VERSION "solectrac-re-0.1"

NS_ :

BS_:

BU_: BMS Charger Dashboard MotorECU VehicleController

BO_ 2565931216 VC_Status: 8 VehicleController
 SG_ VC_State : 7|8@0+ (1,0) [0|255] "" BMS,Charger,MotorECU

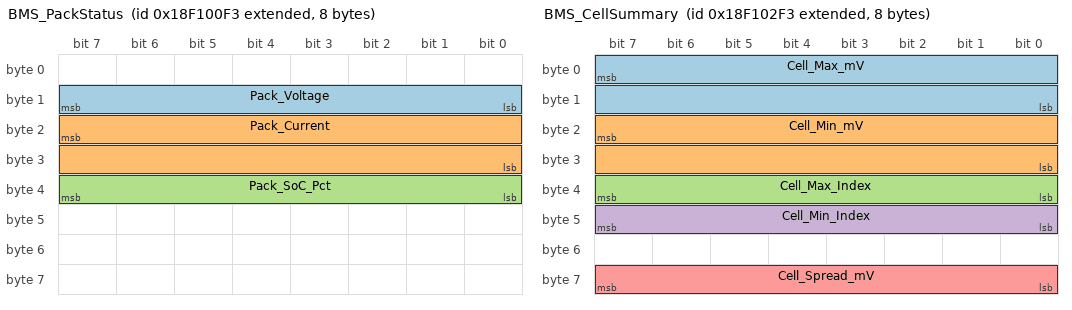
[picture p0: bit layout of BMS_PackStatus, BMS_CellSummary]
BO_ 2565931251 BMS_PackStatus: 8 BMS
 SG_ Pack_Voltage : 15|8@0+ (0.1,76.8) [76.8|102.3] "V" VehicleController,Charger,MotorECU
 SG_ Pack_Current : 23|16@0+ (0.1,-3200) [-3200|3353.5] "A" VehicleController,Charger,MotorECU
 SG_ Pack_SoC_Pct : 39|8@0+ (0.385,3.8) [0|101.975] "%" VehicleController,Charger,MotorECU

BO_ 2565931763 BMS_CellSummary: 8 BMS
 SG_ Cell_Max_mV : 7|16@0+ (1,0) [0|65535] "mV" VehicleController
 SG_ Cell_Min_mV : 23|16@0+ (1,0) [0|65535] "mV" VehicleController
 SG_ Cell_Max_Index : 39|8@0+ (1,0) [0|255] "" VehicleController
 SG_ Cell_Min_Index : 47|8@0+ (1,0) [0|255] "" VehicleController
 SG_ Cell_Spread_mV : 63|8@0+ (1,0) [0|255] "mV" VehicleController

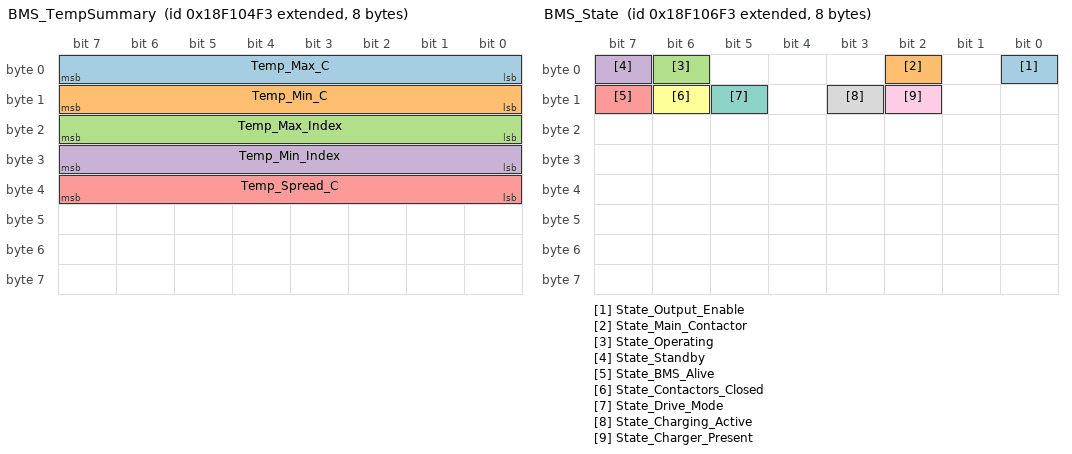
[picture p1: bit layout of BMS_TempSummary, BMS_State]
BO_ 2565932275 BMS_TempSummary: 8 BMS
 SG_ Temp_Max_C : 7|8@0+ (1,-40) [-40|215] "degC" VehicleController
 SG_ Temp_Min_C : 15|8@0+ (1,-40) [-40|215] "degC" VehicleController
 SG_ Temp_Max_Index : 23|8@0+ (1,0) [0|255] "" VehicleController
 SG_ Temp_Min_Index : 31|8@0+ (1,0) [0|255] "" VehicleController
 SG_ Temp_Spread_C : 39|8@0+ (1,0) [0|255] "degC" VehicleController

BO_ 2565932787 BMS_State: 8 BMS
 SG_ State_Output_Enable : 0|1@1+ (1,0) [0|1] "" VehicleController
 SG_ State_Main_Contactor : 2|1@1+ (1,0) [0|1] "" VehicleController
 SG_ State_Operating : 6|1@1+ (1,0) [0|1] "" VehicleController
 SG_ State_Standby : 7|1@1+ (1,0) [0|1] "" VehicleController
 SG_ State_BMS_Alive : 15|1@1+ (1,0) [0|1] "" VehicleController
 SG_ State_Contactors_Closed : 14|1@1+ (1,0) [0|1] "" VehicleController
 SG_ State_Drive_Mode : 13|1@1+ (1,0) [0|1] "" VehicleController
 SG_ State_Charging_Active : 11|1@1+ (1,0) [0|1] "" VehicleController
 SG_ State_Charger_Present : 10|1@1+ (1,0) [0|1] "" VehicleController

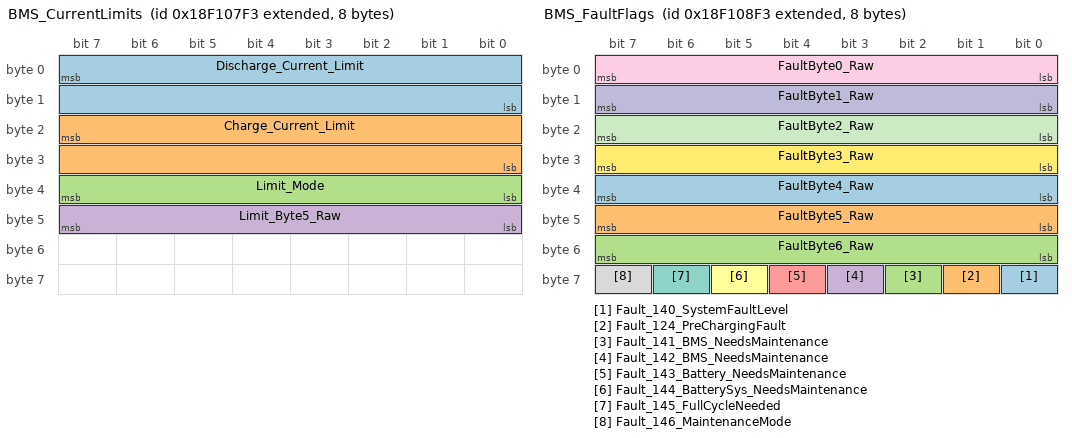
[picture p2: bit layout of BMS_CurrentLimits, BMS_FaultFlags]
BO_ 2565933043 BMS_CurrentLimits: 8 BMS
 SG_ Discharge_Current_Limit : 7|16@0+ (0.01,0) [0|655.35] "A" VehicleController,Charger,MotorECU
 SG_ Charge_Current_Limit : 23|16@0+ (0.01,0) [0|655.35] "A" VehicleController,Charger,MotorECU
 SG_ Limit_Mode : 39|8@0+ (1,0) [0|255] "" VehicleController
 SG_ Limit_Byte5_Raw : 47|8@0+ (1,0) [0|255] "" VehicleController

BO_ 2565933299 BMS_FaultFlags: 8 BMS
 SG_ Fault_140_SystemFaultLevel : 56|1@1+ (1,0) [0|1] "" VehicleController
 SG_ Fault_124_PreChargingFault : 57|1@1+ (1,0) [0|1] "" VehicleController
 SG_ Fault_141_BMS_NeedsMaintenance : 58|1@1+ (1,0) [0|1] "" VehicleController
 SG_ Fault_142_BMS_NeedsMaintenance : 59|1@1+ (1,0) [0|1] "" VehicleController
 SG_ Fault_143_Battery_NeedsMaintenance : 60|1@1+ (1,0) [0|1] "" VehicleController
 SG_ Fault_144_BatterySys_NeedsMaintenance : 61|1@1+ (1,0) [0|1] "" VehicleController
 SG_ Fault_145_FullCycleNeeded : 62|1@1+ (1,0) [0|1] "" VehicleController
 SG_ Fault_146_MaintenanceMode : 63|1@1+ (1,0) [0|1] "" VehicleController
 SG_ FaultByte0_Raw : 0|8@1+ (1,0) [0|255] "" VehicleController
 SG_ FaultByte1_Raw : 8|8@1+ (1,0) [0|255] "" VehicleController
 SG_ FaultByte2_Raw : 16|8@1+ (1,0) [0|255] "" VehicleController
 SG_ FaultByte3_Raw : 24|8@1+ (1,0) [0|255] "" VehicleController
 SG_ FaultByte4_Raw : 32|8@1+ (1,0) [0|255] "" VehicleController
 SG_ FaultByte5_Raw : 40|8@1+ (1,0) [0|255] "" VehicleController
 SG_ FaultByte6_Raw : 48|8@1+ (1,0) [0|255] "" VehicleController

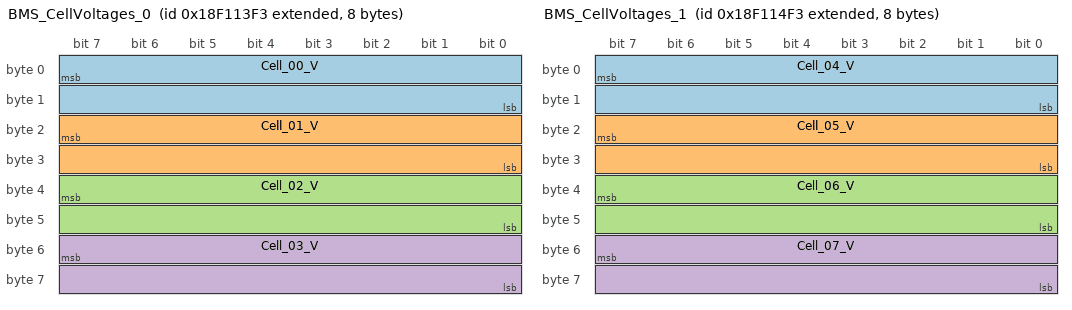
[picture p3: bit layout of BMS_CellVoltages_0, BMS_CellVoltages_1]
BO_ 2565936115 BMS_CellVoltages_0: 8 BMS
 SG_ Cell_00_V : 7|16@0+ (0.001,0) [0|65.535] "V" VehicleController
 SG_ Cell_01_V : 23|16@0+ (0.001,0) [0|65.535] "V" VehicleController
 SG_ Cell_02_V : 39|16@0+ (0.001,0) [0|65.535] "V" VehicleController
 SG_ Cell_03_V : 55|16@0+ (0.001,0) [0|65.535] "V" VehicleController

BO_ 2565936371 BMS_CellVoltages_1: 8 BMS
 SG_ Cell_04_V : 7|16@0+ (0.001,0) [0|65.535] "V" VehicleController
 SG_ Cell_05_V : 23|16@0+ (0.001,0) [0|65.535] "V" VehicleController
 SG_ Cell_06_V : 39|16@0+ (0.001,0) [0|65.535] "V" VehicleController
 SG_ Cell_07_V : 55|16@0+ (0.001,0) [0|65.535] "V" VehicleController

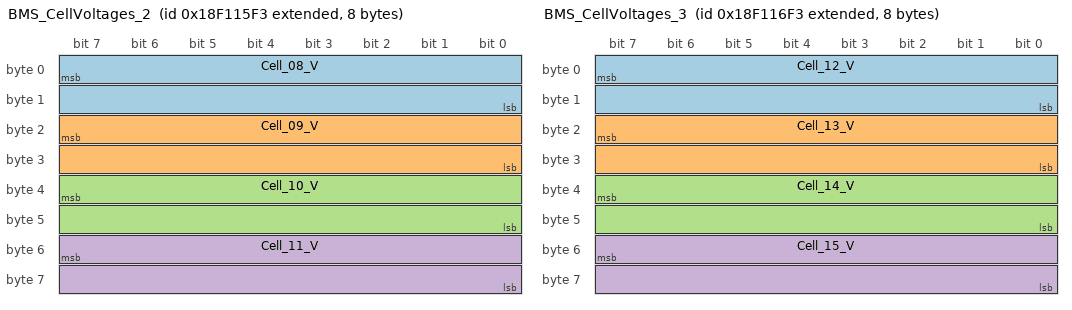
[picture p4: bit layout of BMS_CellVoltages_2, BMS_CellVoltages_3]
BO_ 2565936627 BMS_CellVoltages_2: 8 BMS
 SG_ Cell_08_V : 7|16@0+ (0.001,0) [0|65.535] "V" VehicleController
 SG_ Cell_09_V : 23|16@0+ (0.001,0) [0|65.535] "V" VehicleController
 SG_ Cell_10_V : 39|16@0+ (0.001,0) [0|65.535] "V" VehicleController
 SG_ Cell_11_V : 55|16@0+ (0.001,0) [0|65.535] "V" VehicleController

BO_ 2565936883 BMS_CellVoltages_3: 8 BMS
 SG_ Cell_12_V : 7|16@0+ (0.001,0) [0|65.535] "V" VehicleController
 SG_ Cell_13_V : 23|16@0+ (0.001,0) [0|65.535] "V" VehicleController
 SG_ Cell_14_V : 39|16@0+ (0.001,0) [0|65.535] "V" VehicleController
 SG_ Cell_15_V : 55|16@0+ (0.001,0) [0|65.535] "V" VehicleController

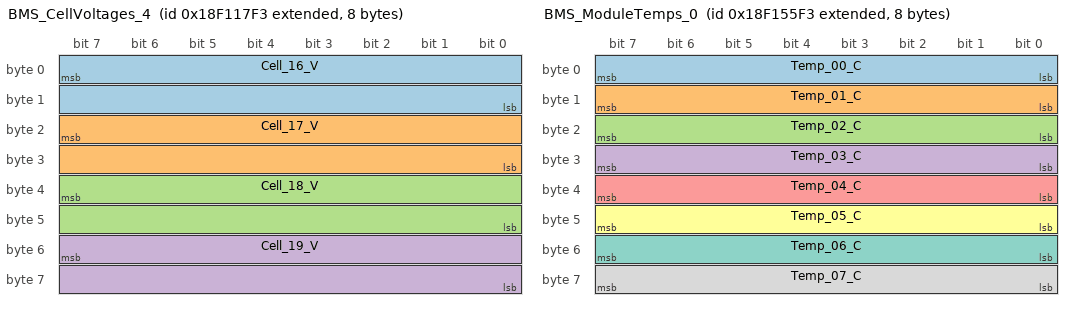
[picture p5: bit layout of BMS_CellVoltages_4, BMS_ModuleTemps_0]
BO_ 2565937139 BMS_CellVoltages_4: 8 BMS
 SG_ Cell_16_V : 7|16@0+ (0.001,0) [0|65.535] "V" VehicleController
 SG_ Cell_17_V : 23|16@0+ (0.001,0) [0|65.535] "V" VehicleController
 SG_ Cell_18_V : 39|16@0+ (0.001,0) [0|65.535] "V" VehicleController
 SG_ Cell_19_V : 55|16@0+ (0.001,0) [0|65.535] "V" VehicleController

BO_ 2565953011 BMS_ModuleTemps_0: 8 BMS
 SG_ Temp_00_C : 7|8@0+ (1,-40) [-40|215] "degC" VehicleController
 SG_ Temp_01_C : 15|8@0+ (1,-40) [-40|215] "degC" VehicleController
 SG_ Temp_02_C : 23|8@0+ (1,-40) [-40|215] "degC" VehicleController
 SG_ Temp_03_C : 31|8@0+ (1,-40) [-40|215] "degC" VehicleController
 SG_ Temp_04_C : 39|8@0+ (1,-40) [-40|215] "degC" VehicleController
 SG_ Temp_05_C : 47|8@0+ (1,-40) [-40|215] "degC" VehicleController
 SG_ Temp_06_C : 55|8@0+ (1,-40) [-40|215] "degC" VehicleController
 SG_ Temp_07_C : 63|8@0+ (1,-40) [-40|215] "degC" VehicleController

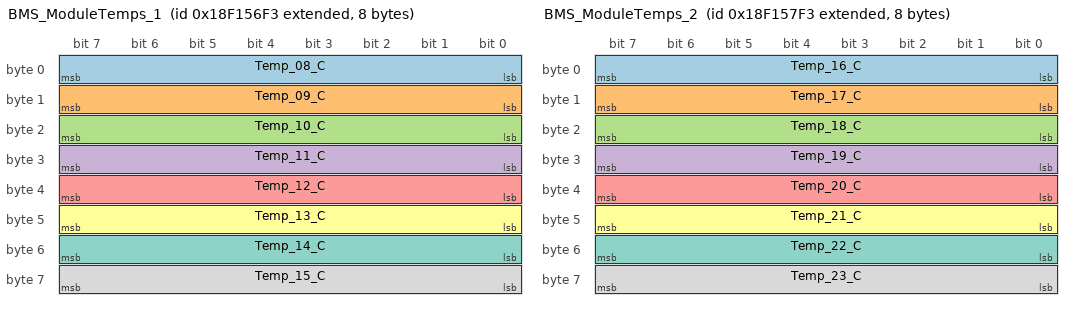
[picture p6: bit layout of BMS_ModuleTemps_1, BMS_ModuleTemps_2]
BO_ 2565953267 BMS_ModuleTemps_1: 8 BMS
 SG_ Temp_08_C : 7|8@0+ (1,-40) [-40|215] "degC" VehicleController
 SG_ Temp_09_C : 15|8@0+ (1,-40) [-40|215] "degC" VehicleController
 SG_ Temp_10_C : 23|8@0+ (1,-40) [-40|215] "degC" VehicleController
 SG_ Temp_11_C : 31|8@0+ (1,-40) [-40|215] "degC" VehicleController
 SG_ Temp_12_C : 39|8@0+ (1,-40) [-40|215] "degC" VehicleController
 SG_ Temp_13_C : 47|8@0+ (1,-40) [-40|215] "degC" VehicleController
 SG_ Temp_14_C : 55|8@0+ (1,-40) [-40|215] "degC" VehicleController
 SG_ Temp_15_C : 63|8@0+ (1,-40) [-40|215] "degC" VehicleController

BO_ 2565953523 BMS_ModuleTemps_2: 8 BMS
 SG_ Temp_16_C : 7|8@0+ (1,-40) [-40|215] "degC" VehicleController
 SG_ Temp_17_C : 15|8@0+ (1,-40) [-40|215] "degC" VehicleController
 SG_ Temp_18_C : 23|8@0+ (1,-40) [-40|215] "degC" VehicleController
 SG_ Temp_19_C : 31|8@0+ (1,-40) [-40|215] "degC" VehicleController
 SG_ Temp_20_C : 39|8@0+ (1,-40) [-40|215] "degC" VehicleController
 SG_ Temp_21_C : 47|8@0+ (1,-40) [-40|215] "degC" VehicleController
 SG_ Temp_22_C : 55|8@0+ (1,-40) [-40|215] "degC" VehicleController
 SG_ Temp_23_C : 63|8@0+ (1,-40) [-40|215] "degC" VehicleController

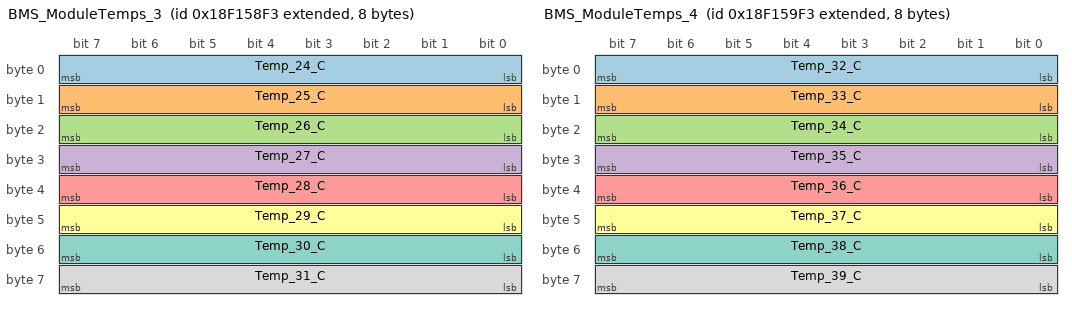
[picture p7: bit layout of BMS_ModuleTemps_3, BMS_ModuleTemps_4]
BO_ 2565953779 BMS_ModuleTemps_3: 8 BMS
 SG_ Temp_24_C : 7|8@0+ (1,-40) [-40|215] "degC" VehicleController
 SG_ Temp_25_C : 15|8@0+ (1,-40) [-40|215] "degC" VehicleController
 SG_ Temp_26_C : 23|8@0+ (1,-40) [-40|215] "degC" VehicleController
 SG_ Temp_27_C : 31|8@0+ (1,-40) [-40|215] "degC" VehicleController
 SG_ Temp_28_C : 39|8@0+ (1,-40) [-40|215] "degC" VehicleController
 SG_ Temp_29_C : 47|8@0+ (1,-40) [-40|215] "degC" VehicleController
 SG_ Temp_30_C : 55|8@0+ (1,-40) [-40|215] "degC" VehicleController
 SG_ Temp_31_C : 63|8@0+ (1,-40) [-40|215] "degC" VehicleController

BO_ 2565954035 BMS_ModuleTemps_4: 8 BMS
 SG_ Temp_32_C : 7|8@0+ (1,-40) [-40|215] "degC" VehicleController
 SG_ Temp_33_C : 15|8@0+ (1,-40) [-40|215] "degC" VehicleController
 SG_ Temp_34_C : 23|8@0+ (1,-40) [-40|215] "degC" VehicleController
 SG_ Temp_35_C : 31|8@0+ (1,-40) [-40|215] "degC" VehicleController
 SG_ Temp_36_C : 39|8@0+ (1,-40) [-40|215] "degC" VehicleController
 SG_ Temp_37_C : 47|8@0+ (1,-40) [-40|215] "degC" VehicleController
 SG_ Temp_38_C : 55|8@0+ (1,-40) [-40|215] "degC" VehicleController
 SG_ Temp_39_C : 63|8@0+ (1,-40) [-40|215] "degC" VehicleController

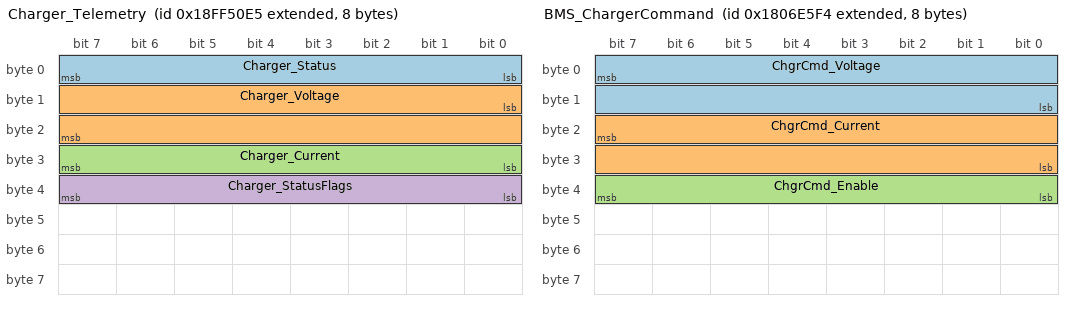
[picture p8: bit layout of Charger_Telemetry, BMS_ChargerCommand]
BO_ 2566869221 Charger_Telemetry: 8 Charger
 SG_ Charger_Status : 0|8@1+ (1,0) [0|255] "" BMS,VehicleController
 SG_ Charger_Voltage : 8|16@1+ (0.1,76.8) [76.8|6630.3] "V" BMS,VehicleController
 SG_ Charger_Current : 24|8@1+ (0.1,0) [0|25.5] "A" BMS,VehicleController
 SG_ Charger_StatusFlags : 32|8@1+ (1,0) [0|255] "" BMS,VehicleController

BO_ 2550588916 BMS_ChargerCommand: 8 BMS
 SG_ ChgrCmd_Voltage : 7|16@0+ (0.1,0) [0|6553.5] "V" Charger
 SG_ ChgrCmd_Current : 23|16@0+ (0.1,0) [0|6553.5] "A" Charger
 SG_ ChgrCmd_Enable : 32|8@1+ (1,0) [0|255] "" Charger

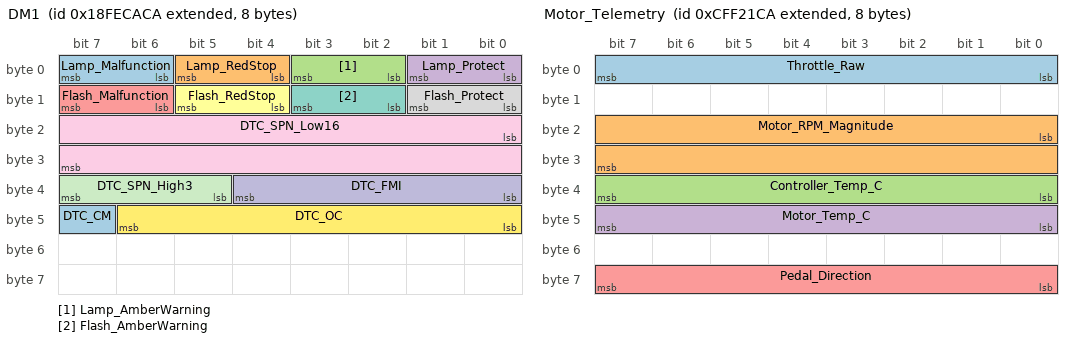
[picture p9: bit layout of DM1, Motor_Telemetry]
BO_ 2566834890 DM1: 8 MotorECU
 SG_ Lamp_Malfunction : 6|2@1+ (1,0) [0|3] "" VehicleController,BMS,Charger
 SG_ Lamp_RedStop : 4|2@1+ (1,0) [0|3] "" VehicleController,BMS,Charger
 SG_ Lamp_AmberWarning : 2|2@1+ (1,0) [0|3] "" VehicleController,BMS,Charger
 SG_ Lamp_Protect : 0|2@1+ (1,0) [0|3] "" VehicleController,BMS,Charger
 SG_ Flash_Malfunction : 14|2@1+ (1,0) [0|3] "" VehicleController,BMS,Charger
 SG_ Flash_RedStop : 12|2@1+ (1,0) [0|3] "" VehicleController,BMS,Charger
 SG_ Flash_AmberWarning : 10|2@1+ (1,0) [0|3] "" VehicleController,BMS,Charger
 SG_ Flash_Protect : 8|2@1+ (1,0) [0|3] "" VehicleController,BMS,Charger
 SG_ DTC_SPN_Low16 : 16|16@1+ (1,0) [0|65535] "" VehicleController,BMS,Charger
 SG_ DTC_FMI : 32|5@1+ (1,0) [0|31] "" VehicleController,BMS,Charger
 SG_ DTC_SPN_High3 : 37|3@1+ (1,0) [0|7] "" VehicleController,BMS,Charger
 SG_ DTC_OC : 40|7@1+ (1,0) [0|127] "" VehicleController,BMS,Charger
 SG_ DTC_CM : 47|1@1+ (1,0) [0|1] "" VehicleController,BMS,Charger

BO_ 2365530570 Motor_Telemetry: 8 MotorECU
 SG_ Throttle_Raw : 0|8@1+ (1,0) [0|255] "" VehicleController
 SG_ Motor_RPM_Magnitude : 16|16@1+ (1,-3200) [-3200|62335] "rpm" VehicleController
 SG_ Controller_Temp_C : 32|8@1+ (1,-40) [-40|215] "degC" VehicleController
 SG_ Motor_Temp_C : 40|8@1+ (1,-40) [-40|215] "degC" VehicleController
 SG_ Pedal_Direction : 56|8@1+ (1,0) [0|255] "" VehicleController

BO_ 2566856978 Dash_Heartbeat: 8 Dashboard
 SG_ Dash_Alive : 0|8@1+ (1,0) [0|255] "" VehicleController,BMS,MotorECU,Charger

CM_ "Solectrac electric tractor CAN database (J1939). Reverse-engineered from observed CAN traffic; not vendor documentation. Do NOT use for safety-relevant decisions. Signals tagged TENTATIVE in their comments are not yet cross-validated against a vendor spec. The companion Python parsers (solectrac-analyze.py, solectrac-stream.py) emit the same content under a parallel namespaced naming scheme — e.g. DBC Pack_Voltage <-> script pack.voltage_v, DBC Cell_NN_V <-> script cell.NN.voltage_v, DBC Fault_<code>_<name> <-> script bms.fault.code_<code>, DBC FaultByteN_Raw <-> script bms.fault.byteN. The encodings are identical; only the naming convention differs.";

CM_ BU_ BMS "Battery management system. J1939 source address 0xF3.";
CM_ BU_ Charger "External charger. J1939 source address 0xE5. Suppresses many BMS frames while not active.";
CM_ BU_ Dashboard "Dashboard / instrument-cluster heartbeat ECU. J1939 source address 0x12 (non-standard). Broadcasts only PGN 0xFF21 at 10 Hz; carries a single 0/1 alive flag in byte 0. The 'Dashboard' label is by elimination from the boot-then-alive pattern coinciding with key-on; not from a vendor table. Powered only with key-on; absent in pure-charging captures (e.g. charging-120V-90ish-to-100.asc) where the BMS+charger talk over CAN without a key in the ignition.";
CM_ BU_ MotorECU "Motor controller / drive ECU. J1939 source address 0xCA. FF21 frame is suppressed entirely while charging (traction contactors open).";
CM_ BU_ VehicleController "Vehicle controller. J1939 source address 0xD0. Broadcasts a minimal F100 heartbeat with a state byte.";

CM_ BO_ 2565931216 "PGN F100 from VehicleController (0xD0). Minimal heartbeat. Byte 0 is the only meaningful field (see VC_State); bytes 1..7 are always 0xFF (J1939 'not available' sentinel) across 22,338 frames in 30 captures and are intentionally not surfaced as DBC signals.";
CM_ SG_ 2565931216 VC_State "Vehicle-controller state byte (PGN F100 from SA 0xD0). Across 22,338 F100D0 frames in 30 captures, only two values are ever observed: 0x00 (init/transition; 19 frames, 0.08%) and 0x0C (ready; 22,319 frames, 99.92%). The 19 init frames all occur in ignition-without-charger-inserted.asc as a brief leading-edge burst (~365 ms cluster) ~0.5-1 s BEFORE the BMS F106 byte-1 state byte transitions between drive_mode (0xE0) and charger_present (0xC4), suggesting VC_State leads BMS mode changes rather than following them. Bytes 1..7 of F100D0 are 0xFF (J1939 'not available' sentinel) in every observed frame and are not surfaced as DBC signals.";

CM_ BO_ 2565931251 "PGN F100 from BMS (0xF3). Pack-level status. Byte 1 = pack terminal voltage; bytes 2-3 = signed pack current; byte 4 = BMS-published State-of-Charge.";
CM_ SG_ 2565931251 Pack_Voltage "Pack voltage at the BMS terminals, 0.1 V/bit with a +76.8 V offset. Confirmed by linear regression against 20 * mean cell mV across 24 captures spanning b2 = 53..65 (82.0..83.3 V); residuals < 0.55 V. Resolution is coarse (0.1 V/bit means 8 mV per cell at 20s), but matches measured pack voltage well. Saturates below 76.8 V; NMC chemistry on this tractor never operates that low.";
CM_ SG_ 2565931251 Pack_Current "Signed pack current. On the wire it is a biased uint16 with raw 0x7D00 = 0 A and 0.1 A/bit (positive = discharge, negative = charge); the DBC expresses this with sign=signed and offset=-3200. Cross-validated against the dashboard reading from 1-58 A across the 0x7D->0x7E and 0x7F->0x80 high-byte rollovers.";
CM_ SG_ 2565931251 Pack_SoC_Pct "BMS-published State-of-Charge, percent. Byte 4 raw saturates at 250 in soc-100-idle.asc and spans 224..250 across charging-120V-90ish-to-100.asc (operator filename indicates a 90%->100% charge); linear fit through (224, 90%) and (250, 100%) gives scale 0.385, offset 3.8. TENTATIVE: dynamic range across our captures is small, so the slope is loose pending a deeper-discharge capture. The voltage-derived SOC estimate from the OCV table can serve as a sanity check.";

CM_ BO_ 2565931763 "PGN F102 from BMS. Cell min/max summary across the whole pack. Layout (corpus survey of 36,950 active frames): bytes 0-1 BE = Cell_Max_mV; bytes 2-3 BE = Cell_Min_mV; byte 4 = Cell_Max_Index (1-based); byte 5 = Cell_Min_Index (1-based); byte 6 = 0x00 padding (constant across corpus); byte 7 = Cell_Spread_mV (1 mV/bit, matches the computed Cell_Max_mV - Cell_Min_mV in 36,950 of 36,950 frames).";
CM_ SG_ 2565931763 Cell_Max_mV "Highest single-cell voltage in the pack, mV.";
CM_ SG_ 2565931763 Cell_Min_mV "Lowest single-cell voltage in the pack, mV.";
CM_ SG_ 2565931763 Cell_Max_Index "1-based cell number (BMS GUI numbering) of the cell reporting Cell_Max_mV. Subtract 1 to map to the 0-based BMS_CellVoltages_* signal index — e.g. value 16 here corresponds to Cell_15_V. CONFIRMED by row-order correlation between F102 frames and surrounding F113..F117 cell-voltage frames in recorded-data/charging.csv: smallest-spread frames report byte 4 = 16 with the contemporaneous max cell at decoder cell_index 15 (= Cell_15_V).";
CM_ SG_ 2565931763 Cell_Min_Index "1-based cell number (BMS GUI numbering) of the cell reporting Cell_Min_mV. Subtract 1 to map to the 0-based BMS_CellVoltages_* signal index. CONFIRMED via the same recorded-data/charging.csv cross-check that anchored Cell_Max_Index.";
CM_ SG_ 2565931763 Cell_Spread_mV "BMS-reported cell spread, byte 7, 1 mV/bit. Verified to equal (Cell_Max_mV - Cell_Min_mV) in 36,950 of 36,950 corpus frames. Previously labelled Cell_Flags pending bit-level decode; the field is in fact a redundant copy of the spread, not a flag bitmap.";

CM_ BO_ 2565932275 "PGN F104 from BMS. Pack temperature min/max summary, mirroring the per-channel data in F155..F15E. Cross-validated byte-for-byte against the decoded per-channel temperatures across multiple captures: byte 0 = max temp, byte 1 = min temp, byte 4 = max-min spread. CONFIRMED.";
CM_ SG_ 2565932275 Temp_Max_C "Highest module temperature in the pack, J1939 +40 C raw offset already removed by the scaling.";
CM_ SG_ 2565932275 Temp_Min_C "Lowest module temperature in the pack, J1939 +40 C raw offset already removed by the scaling.";
CM_ SG_ 2565932275 Temp_Max_Index "1-based channel number of the sensor reporting Temp_Max_C. Subtract 1 to map to the 0-based BMS_ModuleTemps_* signal index.";
CM_ SG_ 2565932275 Temp_Min_Index "1-based channel number of the sensor reporting Temp_Min_C. Subtract 1 to map to the 0-based BMS_ModuleTemps_* signal index.";
CM_ SG_ 2565932275 Temp_Spread_C "Max-Min temperature spread, degC. Equals Temp_Max_C - Temp_Min_C across all observed captures (not a J1939-offset value).";

CM_ BO_ 2565932787 "PGN F106 from BMS. BMS state bitmap; behaviour is charger-dependent. Two state bytes observed (both bit-decoded into the State_* signals below; cantools rejects overlapping signal layouts so neither raw byte is surfaced separately). Across 36,955 F106F3 frames in 30 captures only six (byte0, byte1) clusters appear: (0x45, 0xCC)=28599 active charging, (0x45, 0xE0)=5434 drive ready, (0x80, 0xC4)=2796 charger plugged but no main current, plus (0x45/0x84/0x85, 0xC4) and (0x00, 0x80) as brief boot/teardown transients. Byte 0 is a top-level mode bitfield (output_enable / main_contactor / operating / standby) decoded from the boot and teardown sequences in charging-120V-90ish-to-100.asc; bits 6 (operating) and 7 (standby) are perfectly mutually exclusive across the corpus. Byte 1 carries the secondary bitmap (charger_present / charging / drive_mode / contactors / alive). Byte 2 is constant 0xFC across the corpus (vendor static identifier?); bytes 3-7 are always 0xFF (J1939 'not available'). Observed (byte0, byte1) tuple labels: (0x45, 0xE0)=drive ready, (0x45, 0xCC)=active charging, (0x80, 0xC4)=charger plugged but idle.";
CM_ SG_ 2565932787 State_Output_Enable "Byte 0 bit 0. BMS output command active (drive request or active-charge request enabled). Set in 0x45/0x85; cleared in 0x00/0x44/0x80/0x84. Cleared during plug-in handshake, post-charge teardown, fault-blocked charging, and init.";
CM_ SG_ 2565932787 State_Main_Contactor "Byte 0 bit 2. Main pack contactor closed. Cleared during init (b0=0x00) and after the contactor opens at end of charge (b0=0x80); set in all other observed states. Tracks State_Contactors_Closed (byte 1 bit 6) closely but is sourced from byte 0.";
CM_ SG_ 2565932787 State_Operating "Byte 0 bit 6. Operating mode: power flowing in either direction (driving or actively charging). Set in 0x44/0x45 across all drive captures and during active charging in charging-120V-90ish-to-100.asc. Mutually exclusive with State_Standby across all 36,955 observed frames; cleared only in the init state (b0=0x00).";
CM_ SG_ 2565932787 State_Standby "Byte 0 bit 7. Standby mode: charger plugged in but no main-bus current. Set in 0x80/0x84/0x85; covers plug-in handshake, post-charge idle, and fault-blocked charging (e.g. bms-124-140-142-143-144-146.asc, where faults suspend charging). Mutually exclusive with State_Operating across all 36,955 observed frames.";
CM_ SG_ 2565932787 State_BMS_Alive "Byte 1 bit 7. Set in every observed frame with non-zero state bytes; appears to be a BMS-alive / heartbeat indicator.";
CM_ SG_ 2565932787 State_Contactors_Closed "Byte 1 bit 6. Set when the main contactors are closed (drive mode and active charging); cleared when charger is merely present but idle.";
CM_ SG_ 2565932787 State_Drive_Mode "Byte 1 bit 5. Set in drive captures, clear during charging.";
CM_ SG_ 2565932787 State_Charging_Active "Byte 1 bit 3. Set during active charging; cleared otherwise.";
CM_ SG_ 2565932787 State_Charger_Present "Byte 1 bit 2. Set whenever the charger is plugged in (idle or active); cleared in drive captures.";

CM_ BO_ 2565933043 "PGN F107 from BMS. Active current limits the BMS is authorising on the bus. Bytes 0-1 BE = max discharge current at 0.01 A/bit (145.0 A in drive captures, 100.0 A while charging); bytes 2-3 BE = max charge current at 0.01 A/bit (always 100.0 A in observed captures). These match the manufacturer spec of 200 A peak / 100 A continuous discharge for this 20-cell NMC pack. Byte 4 toggles 0 (charging) / 1 (drive). Byte 5 is a coarse-quantized pack-voltage echo: across 5,326 drive-mode frames it tracks F100F3 pack voltage with R^2=0.97 (V_pack ~= b5*0.2212 + 57.01, step ~0.22 V/bit); 0x00 while charging; rare transient values 0x4D / 0x6B / 0xA7 appear briefly during ignition/teardown windows. Origin (OCV vs terminal vs cell-derived) not yet established.";
CM_ SG_ 2565933043 Discharge_Current_Limit "Maximum allowed discharge current, big-endian uint16 at 0.01 A/bit. Observed values: 145.0 A in drive captures, 100.0 A while charging.";
CM_ SG_ 2565933043 Charge_Current_Limit "Maximum allowed charge current, big-endian uint16 at 0.01 A/bit. Observed value: 100.0 A across all captures.";
CM_ SG_ 2565933043 Limit_Mode "Byte 4. 0 = charge mode (charger present and/or charging), 1 = drive mode. Tracks State_Drive_Mode but is encoded as a u8 here rather than a bit.";
CM_ SG_ 2565933043 Limit_Byte5_Raw "Byte 5. Coarse-quantized pack-voltage echo. Across 5,326 drive-mode frames (b5 in 0x71..0x77 = 113..119), b5 tracks the F100F3 pack-voltage byte with R^2=0.97; per-frame fit V_pack ~= b5*0.2212 + 57.01 (~0.22 V/bit step, i.e. b5 increments once per ~2 ticks of F100 voltage byte). 0x00 in every charge-mode capture. Rare transient values 0x4D (77), 0x6B (107), 0xA7 (167) appear briefly in ignition/teardown windows (5..98 frames each). Origin not yet established (likely an internal voltage limit or OCV estimate). TENTATIVE.";

CM_ BO_ 2565933299 "PGN F108 from BMS. Active fault bitmap; the BMS surfaces operator-visible warning codes here. All bytes are 0x00 in healthy idle (verified against asc/bms-error-codes/idle-no-bms.asc). Byte 7 is a bitmap of dashboard-displayed BMS warning codes. Cross-validated against two operator-confirmed captures in asc/bms-error-codes/: bms-124-140-142-143-144-146.asc (codes 124,140,142,143,144,146; byte 7 = 0xBB = bits 0,1,3,4,5,7) and bms-fullcharge-102-109-140.asc (codes 102,109,140; byte 7 = 0x01 = bit 0). The only code shared by both captures is 140, and the only byte-7 bit shared by both is bit 0 -> bit 0 = 140 (which forces 124 to bit 1, reversing the previous assumption). Bits 3,4,5,7 cover capture-A's remaining codes (142,143,144,146) in numeric order. Bits 2 and 6 weren't lit in either capture, so codes 141 and 145 are SPECULATIVE assignments from the operator manual. Bytes 0..6 surveyed across all 30 captures (36,952 F108 frames): bytes 1,3,4,6 are always 0x00 (reserved padding); byte 0 in {0x00,0x10}; byte 2 in {0x00,0x04}; byte 5 in {0x00,0x01}; only six (b0,b2,b5,b7) tuples ever appear: (00,00,00,00), (10,04,00,01), (10,04,00,B9), (00,00,01,BB), and two transient outliers (10,00,00,01) and (00,00,00,B8) seen in <5 frames each. Byte 0 bit 4 and byte 2 bit 2 are paired (set/clear together in 36,949/36,952 frames) and are set exactly when byte 7 has code 140 active and code 124 clear; byte 5 bit 0 is set exactly when byte 7 has code 124 active. They mirror state already encoded in byte 7 rather than introducing new codes. Codes 102 and 109 (visible on the dashboard during bms-fullcharge-102-109-140.asc) are NOT transmitted on F108 -- byte 0/2/5 take their usual paired values for 'code 140 only', and the dashboard must be sourcing 102/109 from somewhere else (likely derived from voltage thresholds rather than carried on this PGN). The vendor BMS error-code table is from the operator manual (codes 100-113, 116-127, 140, 142-146).";
CM_ SG_ 2565933299 Fault_140_SystemFaultLevel "BMS code 140: System fault: kvst. Bit 0 of byte 7. CONFIRMED: this is the single bit shared between the two F108 calibration captures (capture A bits 0,1,3,4,5,7 vs capture B bit 0).";
CM_ SG_ 2565933299 Fault_124_PreChargingFault "BMS code 124: Pre-charging fault. Bit 1 of byte 7. CONFIRMED by elimination once Fault_140 was anchored to bit 0; previous mapping (bit 0 = 124) was wrong.";
CM_ SG_ 2565933299 Fault_141_BMS_NeedsMaintenance "BMS code 141: BMS fault, needs maintenance. Bit 2 of byte 7. SPECULATIVE: bit 2 wasn't lit in either calibration capture; assignment is from the operator-manual numeric ordering.";
CM_ SG_ 2565933299 Fault_142_BMS_NeedsMaintenance "BMS code 142: BMS fault, needs maintenance. Bit 3 of byte 7. TENTATIVE: 142 is not in the operator-manual table (which lists 141 instead), but the capture-A bit pattern requires a code at bit 3 and 142 is the value the dashboard displayed.";
CM_ SG_ 2565933299 Fault_143_Battery_NeedsMaintenance "BMS code 143: Battery fault, needs maintenance.";
CM_ SG_ 2565933299 Fault_144_BatterySys_NeedsMaintenance "BMS code 144: Battery system fault, needs maintenance.";
CM_ SG_ 2565933299 Fault_145_FullCycleNeeded "BMS code 145: The battery needs to maintenance (full charging and full discharging). Bit 6 of byte 7. SPECULATIVE: bit 6 wasn't lit in either calibration capture; assignment is from the operator-manual numeric ordering.";
CM_ SG_ 2565933299 Fault_146_MaintenanceMode "BMS code 146: Maintenance mode status.";
CM_ SG_ 2565933299 FaultByte0_Raw "Byte 0 of F108. Across 36,952 F108 frames in 30 captures, this byte takes only two values: 0x00 or 0x10 (only bit 4 ever lit). Bit 4 is set exactly when byte 7 has code 140 active AND code 124 clear (i.e. byte 7 in {0x01, 0xB9}). It tracks byte 2 bit 2 (paired in all but 3 transient frames) and appears to mirror byte-7 state rather than encode a new code. Surfaced as raw u8 for forward compatibility.";
CM_ SG_ 2565933299 FaultByte1_Raw "Byte 1 of F108. 0x00 in all 36,952 observed F108 frames across 30 captures. Reserved padding. Surfaced as raw u8 for forward compatibility.";
CM_ SG_ 2565933299 FaultByte2_Raw "Byte 2 of F108. Across 36,952 F108 frames in 30 captures, this byte takes only two values: 0x00 or 0x04 (only bit 2 ever lit). Bit 2 is paired with byte 0 bit 4 (set/clear together in all but 3 transient frames) and is set exactly when byte 7 has code 140 active AND code 124 clear. Mirrors byte-7 state rather than encoding a new code. Surfaced as raw u8 for forward compatibility.";
CM_ SG_ 2565933299 FaultByte3_Raw "Byte 3 of F108. 0x00 in all 36,952 observed F108 frames across 30 captures. Reserved padding. Surfaced as raw u8 for forward compatibility.";
CM_ SG_ 2565933299 FaultByte4_Raw "Byte 4 of F108. 0x00 in all 36,952 observed F108 frames across 30 captures. Reserved padding. Surfaced as raw u8 for forward compatibility.";
CM_ SG_ 2565933299 FaultByte5_Raw "Byte 5 of F108. Across 36,952 F108 frames in 30 captures, this byte takes only two values: 0x00 or 0x01 (only bit 0 ever lit). Bit 0 is set exactly when byte 7 has code 124 (Pre-charging fault) active. Mirrors byte-7 state rather than encoding a new code. Surfaced as raw u8 for forward compatibility.";
CM_ SG_ 2565933299 FaultByte6_Raw "Byte 6 of F108. 0x00 in all 36,952 observed F108 frames across 30 captures. Reserved padding. Surfaced as raw u8 for forward compatibility.";

CM_ BO_ 2565936115 "PGN F113 from BMS. Cell voltages 0..3.";
CM_ BO_ 2565936371 "PGN F114 from BMS. Cell voltages 4..7.";
CM_ BO_ 2565936627 "PGN F115 from BMS. Cell voltages 8..11.";
CM_ BO_ 2565936883 "PGN F116 from BMS. Cell voltages 12..15.";
CM_ BO_ 2565937139 "PGN F117 from BMS. Cell voltages 16..19. PGNs F118..F13C are reserved by the BMS for larger packs but unused on this 20-cell tractor.";

CM_ BO_ 2565953011 "PGN F155 from BMS. Module temperatures 0..7. J1939-style +40 C raw offset already removed by the scaling.";
CM_ BO_ 2565953267 "PGN F156 from BMS. Module temperatures 8..15.";
CM_ BO_ 2565953523 "PGN F157 from BMS. Module temperatures 16..23.";
CM_ BO_ 2565953779 "PGN F158 from BMS. Module temperatures 24..31. The actual number of populated channels on this tractor is not yet confirmed; unused channels broadcast as 0 and should be filtered out (0 raw = -40 C).";
CM_ BO_ 2565954035 "PGN F159 from BMS. Module temperatures 32..39. PGNs F15A..F15E are reserved for larger packs.";

CM_ BO_ 2566869221 "PGN FF50 from external Charger (0xE5). Charger output telemetry. Layout (corpus survey of 3,108 frames in 5 of 30 captures): byte 0 = Charger_Status; bytes 1-2 LE = Charger_Voltage (0.1 V/bit, +76.8 V offset); byte 3 = Charger_Current (0.1 A/bit, 8-bit, NOT 16-bit LE); byte 4 = Charger_StatusFlags bitmap (NOT a current high byte); bytes 5-7 = 0x00 padding (constant across every observed frame).";
CM_ SG_ 2566869221 Charger_Status "Charger status byte. 0x00 = idle / not charging (charger module idle or session ended); 0x01 / 0x02 = brief state-transition values seen during handshake; 0x03 = ACTIVE charging. Established by asc/charging-120V-90ish-to-100.asc, in which 2863 of 3007 charger frames were status=0x03 with byte1 / byte3 tracking pack voltage and current respectively, then status switched to 0x00 with both data bytes pinned low for the final 134 frames once charging finished. Earlier captures only contained handshake/idle frames and were misleading.";
CM_ SG_ 2566869221 Charger_Voltage "Charger output voltage at the pack terminals. Encoded identically to Pack_Voltage in BMS_PackStatus: 0.1 V/bit with a +76.8 V offset. Anchored against asc/charging-120V-90ish-to-100.asc by linear regression of byte1 vs Pack_Voltage across 2863 active-charging frames: slope 0.1024, intercept 77.04, R^2=0.9856. Tracks Pack_Voltage to within 0.6 V across the whole charge (charger reads slightly lower than the BMS, consistent with cable voltage drop). Byte 2 (high byte of the 16-bit LE field) was 0x00 throughout the 120V capture; the pack will never reach 102.3 V with this 20-cell NMC chemistry, so the high byte may always be 0 in practice. ONLY MEANINGFUL WHEN Charger_Status == 'active' (0x03); other statuses leave the bytes at handshake / idle values that should not be interpreted as voltage.";
CM_ SG_ 2566869221 Charger_Current "Charger output current magnitude. 0.1 A/bit, no offset; byte 3 ONLY (8-bit, NOT 16-bit LE as previously assumed). Anchored against |Pack_Current| in F100F3 across 2863 active-charging frames: slope 0.0989, intercept -0.07, R^2=0.9985. Tracks |Pack_Current| to within 0.3 A across the whole charge, including the constant-current to constant-voltage taper near full SOC (18.5 A -> 9.9 A -> 2.9 A as the pack approached 100%). Byte 4 -- previously assumed to be the high byte of a 16-bit current field -- is in fact a status-flags bitmap (see Charger_StatusFlags); byte 4 = 0x08 in idle is the line-OK flag, NOT 204.8 A as a 16-bit decode would suggest. ONLY MEANINGFUL WHEN Charger_Status == 'active' (0x03) AND Charger_StatusFlags == 0x00; other states leave byte 3 at handshake / idle values.";
CM_ SG_ 2566869221 Charger_StatusFlags "Charger status-flags bitmap (byte 4). Surveyed across all 5 captures with Charger frames (3,108 frames total). Observed bit assignments: bit 2 = output disabled, bit 3 = AC line OK, bit 4 = AC line not detected. Common patterns: 0x00 (active charging, valid V/I in bytes 1-3), 0x08 (line OK, output disabled / idle), 0x14 (output disabled + no line). Bit-level signals are NOT split out separately because cantools strict mode rejects bit-level overlaps with the parent byte-level signal; consumers should mask: (flags & 0x04) for output-disabled, (flags & 0x08) for line-OK, (flags & 0x10) for no-line. When status==0x03 AND flags==0x00, bytes 1-3 carry valid V/I telemetry; otherwise they hold leftover or handshake values that should not be interpreted as physical quantities.";

CM_ BO_ 2566834890 "PGN FECA (DM1, Active Diagnostic Trouble Codes) from MotorECU (0xCA), per SAE J1939-73. Single-frame layout: bytes 0/1 = lamp/flash status (4 lamps x 2 bits each), bytes 2-5 = first DTC (SPN/FMI/CM/OC), bytes 6-7 = padding 0xFF. The full SPN is 19 bits and is reconstructed as SPN = DTC_SPN_Low16 | (DTC_SPN_High3 << 16); DBC can't express that as a single signal because the bits aren't contiguous. The decoder also assumes SPN Conversion Method = 0 (DTC_CM bit, modern J1939); if a frame ever shows DTC_CM = 1 the bit packing of byte 4 changes and the SPN/FMI fields must be re-decoded. Multi-DTC DM1 messages travel over J1939 transport-protocol BAM (PGN ECFF/EBFF) and aren't represented in this DBC -- none have been observed in our captures so far. Every observed DM1 frame in current captures is the J1939 idle pattern (00 00 00 00 00 00 FF FF), so the lamp/state encoding is validated against the J1939-73 spec rather than against fault data; treat any future SPN as TENTATIVE until cross-checked against vendor docs.";
CM_ SG_ 2566834890 Lamp_Malfunction "Malfunction Indicator Lamp (MIL) status, byte 0 bits 7-6. 0=off, 1=on, 2=reserved, 3=not available.";
CM_ SG_ 2566834890 Lamp_RedStop "Red Stop Lamp status, byte 0 bits 5-4. Same enum as Lamp_Malfunction.";
CM_ SG_ 2566834890 Lamp_AmberWarning "Amber Warning Lamp status, byte 0 bits 3-2. Same enum as Lamp_Malfunction.";
CM_ SG_ 2566834890 Lamp_Protect "Protect Lamp status, byte 0 bits 1-0. Same enum as Lamp_Malfunction.";
CM_ SG_ 2566834890 Flash_Malfunction "MIL flash status, byte 1 bits 7-6. 0=no flash, 1=slow (1 Hz), 2=fast (2 Hz), 3=not available.";
CM_ SG_ 2566834890 Flash_RedStop "Red Stop flash status, byte 1 bits 5-4. Same enum as Flash_Malfunction.";
CM_ SG_ 2566834890 Flash_AmberWarning "Amber Warning flash status, byte 1 bits 3-2. Same enum as Flash_Malfunction.";
CM_ SG_ 2566834890 Flash_Protect "Protect Lamp flash status, byte 1 bits 1-0. Same enum as Flash_Malfunction.";
CM_ SG_ 2566834890 DTC_SPN_Low16 "Lower 16 bits of the 19-bit Suspect Parameter Number, bytes 2-3 little-endian. Combine with DTC_SPN_High3 to reconstruct the full SPN.";
CM_ SG_ 2566834890 DTC_FMI "Failure Mode Indicator (5 bits), byte 4 bits 0-4. Standard SAE J1939-73 FMI table (0=above-range high, 1=below-range low, 2=erratic, 3=shorted high, 4=shorted low, 5=open circuit, ... 31=condition exists).";
CM_ SG_ 2566834890 DTC_SPN_High3 "Upper 3 bits of the 19-bit SPN, byte 4 bits 5-7. Combine with DTC_SPN_Low16: SPN = DTC_SPN_Low16 | (DTC_SPN_High3 << 16).";
CM_ SG_ 2566834890 DTC_OC "Occurrence Count, byte 5 bits 0-6. Number of times this DTC has been activated since the last clear; saturates at 126; raw 127 = not available.";
CM_ SG_ 2566834890 DTC_CM "SPN Conversion Method bit, byte 5 bit 7. 0 = modern (this DBC's bit-packing); 1 = legacy (bytes 4-5 use a different SPN/FMI layout that this DBC does NOT represent).";

CM_ BO_ 2550588916 "PGN 0x000600 (PDU1, dest 0xE5) from BMS in its charger-interface role (source address 0xF4 -- distinct from the BMS broadcast address 0xF3). Vendor-proprietary BMS->Charger setpoint command. The BMS publishes its V/I request to the external charger; the charger then mirrors the request in its FF50 telemetry (Charger_Voltage / Charger_Current) up to its delivery capability. Reverse-engineered against asc/charging-120V-90ish-to-100.asc (61,259 frames) by correlating contemporaneous Charger_Telemetry, BMS_PackStatus, and BMS_CurrentLimits. Idle-pattern frames are 00 00 00 00 01 FF FF FF; active-request frames carry V_setpoint = 0x034E (84.6 V = 4.23 V/cell * 20 cells, the NMC max charge voltage) for the entire charge while I_setpoint tapers from 39 A down to 3 A as SOC approaches 100%.";
CM_ SG_ 2550588916 ChgrCmd_Voltage "BMS-commanded charger voltage setpoint, bytes 0-1 big-endian, 0.1 V/bit, NO offset (unlike Pack_Voltage / Charger_Voltage which both carry a +76.8 V offset). Always 84.6 V during active requests in the observed 20s NMC pack. Bytes are 0x0000 during idle frames; consumers should ignore the field when ChgrCmd_Enable == 1.";
CM_ SG_ 2550588916 ChgrCmd_Current "BMS-commanded charger current setpoint, bytes 2-3 big-endian, 0.1 A/bit, no offset. Observed range 3.0..39.0 A across a 90%->100% charge; Charger_Current tracks within ~0.5 A when the request is within delivery capability and saturates near the line-side limit otherwise (e.g. ~18 A on a 120 V / 15 A wall outlet). Bytes are 0x0000 during idle frames.";
CM_ SG_ 2550588916 ChgrCmd_Enable "Enable flag for the V/I request, byte 4. 0x00 = active charging request (charger should track the V/I setpoints); 0x01 = idle / no request (charger drops Charger_Status to 0x00 within a few frames). Bytes 5-7 are padding 0xFF.";

CM_ BO_ 2365530570 "PGN FF21 from MotorECU (0xCA). Motor / drive telemetry. Frame priority is 3 (not 6), so the on-the-wire 29-bit ID is 0x0CFF21CA. Suppressed entirely while charging (traction contactors open). Byte layout (across 45,086 frames in 30 captures): byte 0 = Throttle_Raw (range 0x00..0x69), byte 1 = reserved padding (always 0x00), bytes 2-3 = Motor_RPM_Magnitude LE u16 biased by 0x0C80, byte 4 = Controller_Temp_C (+40 C offset, 0=absent), byte 5 = Motor_Temp_C (+40 C offset, 0=absent), byte 6 = reserved padding (always 0x00), byte 7 = Pedal_Direction (0x10/0x14/0x18). Bytes 1 and 6 are not surfaced as DBC signals because they are confirmed reserved padding across the entire corpus; if a future capture ever shows them nonzero they should be added.";
CM_ SG_ 2365530570 Throttle_Raw "Throttle pedal position, raw. Across all 45,086 motor-telemetry frames in the 30-capture corpus, byte 0 ranges 0..0x69 (0..105). Behaves like a J1939-style 0..100% percent field with an idle resting offset of ~3 (sensor noise floor with foot off pedal) and a controller dead-low around 14 (below this, motor RPM stays near 0; a TPS_dead_low band is a generic Curtis/Kelly traction-controller idiom). Rare excursions to 105 (e.g. amperage-readings/amp-58.asc) are mechanical pedal overshoot. Recommended display formula: pct = clamp(0, 100, raw - 3).";
CM_ SG_ 2365530570 Motor_RPM_Magnitude "Motor RPM magnitude (always >= 0). On the wire it is a biased little-endian uint16: raw 0x0C80 = 0 rpm; the DBC expresses this with offset=-3200. Sign of motion comes from Pedal_Direction, not from this field. Verified against a 0..2500 rpm acceleration trace.";
CM_ SG_ 2365530570 Controller_Temp_C "Main controller temperature, byte 4. J1939 +40 C offset; raw 0 means 'not present in this frame' and should be filtered. Identified vs Motor_Temp_C by the cold-start ramp in asc/ignition-without-charger-inserted.asc (byte 4 climbs 0->19 C while byte 5 stays at 13 C); inverter electronics typically run hotter than the motor housing.";
CM_ SG_ 2365530570 Motor_Temp_C "Motor temperature, byte 5. J1939 +40 C offset; raw 0 means 'not present in this frame' and should be filtered. Consistently a few degrees cooler than Controller_Temp_C across all observed captures.";
CM_ SG_ 2365530570 Pedal_Direction "Foot-pedal selector. 0x10 = idle / neither pedal, 0x14 = forward pedal pressed, 0x18 = reverse pedal pressed. Verified by correlating driving-trace transitions with operator-reported maneuvers.";

CM_ BO_ 2566856978 "PGN FF21 from Dashboard (SA 0x12). Same PGN as Motor_Telemetry but a different sender, so the on-the-wire 29-bit ID is 0x18FF2112 (vs 0x0CFF21CA for the motor). 10 Hz cadence (median 97 ms period). Source address 0x12 is non-standard and broadcasts ONLY this PGN; the 'Dashboard' label is by elimination, not from a vendor table. Across 30 captures (6634 frames total) only two payloads have ever been seen: 0000000000000000 (15 frames, all in the first ~700 ms after key-on in the two ignition-* captures) and 0100000000000000 (the other 6619 frames). Bytes 1..7 are reserved padding (always 0x00).";
CM_ SG_ 2566856978 Dash_Alive "Dashboard alive flag, byte 0. 0 = booting (first ~700 ms after key-on); 1 = ready / alive (steady value thereafter, 10 Hz). Useful as a liveness check: if this signal stops updating the dashboard ECU has dropped off the bus.";

VAL_ 2565931216 VC_State 0 "init" 12 "ready" ;
VAL_ 2566869221 Charger_Status 0 "idle" 1 "transient_01" 2 "transient_02" 3 "active" ;
VAL_ 2365530570 Pedal_Direction 16 "idle" 20 "forward" 24 "reverse" ;
VAL_ 2565933299 Fault_140_SystemFaultLevel 0 "inactive" 1 "active" ;
VAL_ 2565933299 Fault_124_PreChargingFault 0 "inactive" 1 "active" ;
VAL_ 2565933299 Fault_141_BMS_NeedsMaintenance 0 "inactive" 1 "active" ;
VAL_ 2565933299 Fault_142_BMS_NeedsMaintenance 0 "inactive" 1 "active" ;
VAL_ 2565933299 Fault_143_Battery_NeedsMaintenance 0 "inactive" 1 "active" ;
VAL_ 2565933299 Fault_144_BatterySys_NeedsMaintenance 0 "inactive" 1 "active" ;
VAL_ 2565933299 Fault_145_FullCycleNeeded 0 "inactive" 1 "active" ;
VAL_ 2565933299 Fault_146_MaintenanceMode 0 "inactive" 1 "active" ;
VAL_ 2565932787 State_Output_Enable 0 "off" 1 "on" ;
VAL_ 2565932787 State_Main_Contactor 0 "open" 1 "closed" ;
VAL_ 2565932787 State_Operating 0 "no" 1 "yes" ;
VAL_ 2565932787 State_Standby 0 "no" 1 "yes" ;
VAL_ 2565932787 State_BMS_Alive 0 "no" 1 "yes" ;
VAL_ 2565932787 State_Contactors_Closed 0 "open" 1 "closed" ;
VAL_ 2565932787 State_Drive_Mode 0 "inactive" 1 "active" ;
VAL_ 2565932787 State_Charging_Active 0 "inactive" 1 "active" ;
VAL_ 2565932787 State_Charger_Present 0 "absent" 1 "present" ;
VAL_ 2565933043 Limit_Mode 0 "charge" 1 "drive" ;
VAL_ 2566834890 Lamp_Malfunction 0 "off" 1 "on" 2 "reserved" 3 "n/a" ;
VAL_ 2566834890 Lamp_RedStop 0 "off" 1 "on" 2 "reserved" 3 "n/a" ;
VAL_ 2566834890 Lamp_AmberWarning 0 "off" 1 "on" 2 "reserved" 3 "n/a" ;
VAL_ 2566834890 Lamp_Protect 0 "off" 1 "on" 2 "reserved" 3 "n/a" ;
VAL_ 2566834890 Flash_Malfunction 0 "no_flash" 1 "slow_1Hz" 2 "fast_2Hz" 3 "n/a" ;
VAL_ 2566834890 Flash_RedStop 0 "no_flash" 1 "slow_1Hz" 2 "fast_2Hz" 3 "n/a" ;
VAL_ 2566834890 Flash_AmberWarning 0 "no_flash" 1 "slow_1Hz" 2 "fast_2Hz" 3 "n/a" ;
VAL_ 2566834890 Flash_Protect 0 "no_flash" 1 "slow_1Hz" 2 "fast_2Hz" 3 "n/a" ;
VAL_ 2566834890 DTC_FMI 0 "above_max" 1 "below_min" 2 "erratic" 3 "shorted_high" 4 "shorted_low" 5 "open_circuit" 6 "shorted_ground" 7 "wrong_response" 8 "abnormal_freq" 9 "abnormal_update" 10 "abnormal_change" 11 "unknown" 12 "bad_device" 13 "out_of_cal" 14 "special" 15 "info_high_least" 16 "info_high_mod" 17 "info_low_least" 18 "info_low_mod" 19 "data_error" 20 "drift_high" 21 "drift_low" 31 "condition_exists" ;
VAL_ 2566834890 DTC_CM 0 "modern" 1 "legacy" ;
VAL_ 2550588916 ChgrCmd_Enable 0 "active_request" 1 "idle" ;
VAL_ 2566856978 Dash_Alive 0 "booting" 1 "alive" ;
